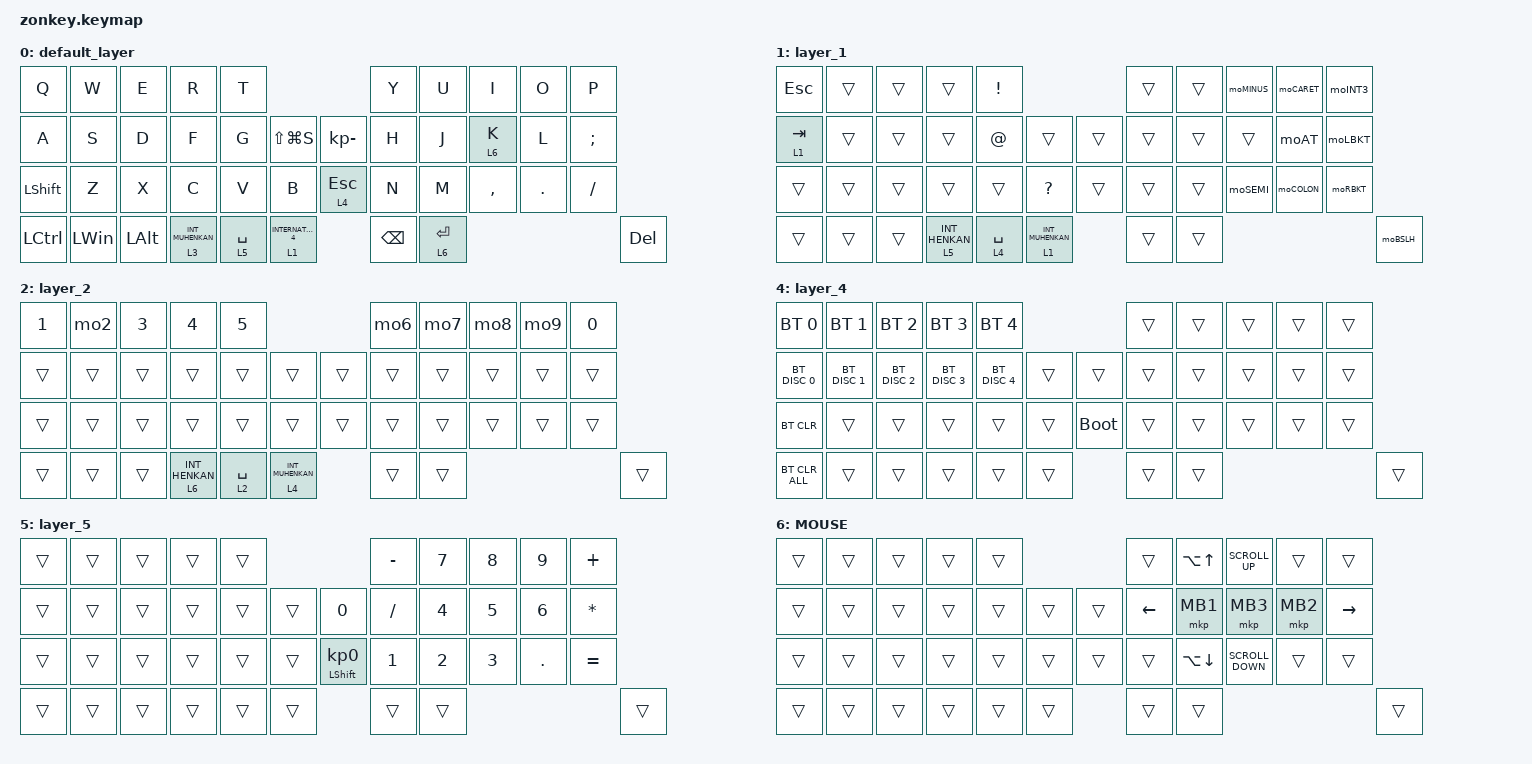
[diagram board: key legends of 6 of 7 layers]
#include <behaviors.dtsi>
#include <dt-bindings/zmk/bt.h>
#include <dt-bindings/zmk/keys.h>
#include <dt-bindings/zmk/pointing.h>

#define ZMK_POINTING_DEFAULT_SCRL_VAL 100
#define JIS 1
#define BT 4
#define MOUSE 6

&mt {
    flavor = "balanced";
    quick-tap-ms = <0>;
};

/ {
    combos { compatible = "zmk,combos"; };

    macros {
        to_layer_0: to_layer_0 {
            compatible = "zmk,behavior-macro-one-param";
            #binding-cells = <1>;
            bindings = <&to 0 &macro_param_1to1 &kp MACRO_PLACEHOLDER>;
            label = "TO_LAYER_0";
        };
    };

    behaviors {
        lt_to_layer_0: lt_to_layer_0 {
            compatible = "zmk,behavior-hold-tap";
            label = "LAYER_TAP_TO_0";
            bindings = <&mo>, <&to_layer_0>;

            #binding-cells = <2>;
            tapping-term-ms = <10>;
        };

        toJIS: toJIS {
            compatible = "zmk,behavior-hold-tap";
            label = "toJIS";
            #binding-cells = <2>;
            tapping-term-ms = <200>;
            quick-tap-ms = <0>;
            bindings = <&tog>, <&kp>;
        };

        mo2: mo2 {
            compatible = "zmk,behavior-mod-morph";
            #binding-cells = <0>;
            bindings = <&kp N2>, <&kp DQT>;

            mods = <(MOD_LSFT|MOD_RSFT)>;
        };

        mo6: mo6 {
            compatible = "zmk,behavior-mod-morph";
            #binding-cells = <0>;
            bindings = <&kp N6>, <&kp AMPS>;

            mods = <(MOD_LSFT|MOD_RSFT)>;
        };

        mo7: mo7 {
            compatible = "zmk,behavior-mod-morph";
            #binding-cells = <0>;
            bindings = <&kp N7>, <&kp APOS>;

            mods = <(MOD_LSFT|MOD_RSFT)>;
        };

        mo8: mo8 {
            compatible = "zmk,behavior-mod-morph";
            #binding-cells = <0>;
            bindings = <&kp N8>, <&kp LPAR>;

            mods = <(MOD_LSFT|MOD_RSFT)>;
        };

        mo9: mo9 {
            compatible = "zmk,behavior-mod-morph";
            #binding-cells = <0>;
            bindings = <&kp N9>, <&kp RPAR>;

            mods = <(MOD_LSFT|MOD_RSFT)>;
        };

        moMINUS: moMINUS {
            compatible = "zmk,behavior-mod-morph";
            #binding-cells = <0>;
            bindings = <&kp MINUS>, <&kp EQUAL>;

            mods = <(MOD_LSFT|MOD_RSFT)>;
        };

        moCARET: moCARET {
            compatible = "zmk,behavior-mod-morph";
            #binding-cells = <0>;
            bindings = <&kp CARET>, <&kp TILDE>;

            mods = <(MOD_LSFT|MOD_RSFT)>;
        };

        moINT3: moINT3 {
            compatible = "zmk,behavior-mod-morph";
            #binding-cells = <0>;
            bindings = <&kp INT3>, <&kp PIPE>;

            mods = <(MOD_LSFT|MOD_RSFT)>;
        };

        moAT: moAT {
            compatible = "zmk,behavior-mod-morph";
            #binding-cells = <0>;
            bindings = <&kp AT>, <&kp GRAVE>;

            mods = <(MOD_LSFT|MOD_RSFT)>;
        };

        moLBKT: moLBKT {
            compatible = "zmk,behavior-mod-morph";
            #binding-cells = <0>;
            bindings = <&kp LBKT>, <&kp LS(LBRC)>;

            mods = <(MOD_LSFT|MOD_RSFT)>;
        };

        moRBKT: moRBKT {
            compatible = "zmk,behavior-mod-morph";
            #binding-cells = <0>;
            bindings = <&kp RBKT>, <&kp LS(RBRC)>;

            mods = <(MOD_LSFT|MOD_RSFT)>;
        };

        moSEMI: moSEMI {
            compatible = "zmk,behavior-mod-morph";
            #binding-cells = <0>;
            bindings = <&kp SEMI>, <&kp PLUS>;

            mods = <(MOD_LSFT|MOD_RSFT)>;
        };

        moCOLON: moCOLON {
            compatible = "zmk,behavior-mod-morph";
            #binding-cells = <0>;
            bindings = <&kp COLON>, <&kp ASTRK>;

            mods = <(MOD_LSFT|MOD_RSFT)>;
        };

        moBSLH: moBSLH {
            compatible = "zmk,behavior-mod-morph";
            #binding-cells = <0>;
            bindings = <&kp BSLH>, <&kp UNDER>;

            mods = <(MOD_LSFT|MOD_RSFT)>;
        };

        scroll_down_up: behavior_sensor_rotate_mouse_wheel_down_up {
            compatible = "zmk,behavior-sensor-rotate";
            #sensor-binding-cells = <0>;
            bindings = <&msc SCRL_DOWN>, <&msc SCRL_UP>;

            tap-ms = <20>;
        };
    };

    keymap {
        compatible = "zmk,keymap";

        default_layer {
            bindings = <
&kp Q           &kp W         &kp E         &kp R               &kp T                                               &kp Y          &kp U        &kp I      &kp O    &kp P
&kp A           &kp S         &kp D         &kp F               &kp G        &kp LS(LG(S))            &kp KP_MINUS  &kp H          &kp J        &lt 6 K    &kp L    &kp SEMI
&kp LEFT_SHIFT  &kp Z         &kp X         &kp C               &kp V        &kp B                    &lt 4 ESCAPE  &kp N          &kp M        &kp COMMA  &kp DOT  &kp SLASH
&kp LCTRL       &kp LEFT_WIN  &kp LEFT_ALT  &lt 3 INT_MUHENKAN  &lt 5 SPACE  &lt 1 INTERNATIONAL_4                  &kp BACKSPACE  &lt 6 ENTER                                 &kp DEL
            >;

            sensor-bindings =
                <&scroll_down_up>,
                <&inc_dec_kp C_VOL_DN C_VOL_UP>;
        };

        layer_1 {
            bindings = <
&kp ESCAPE    &trans  &trans  &trans            &kp EXCLAMATION                                &trans  &trans  &moMINUS  &moCARET  &moINT3
&toJIS 1 TAB  &trans  &trans  &trans            &kp AT           &trans                &trans  &trans  &trans  &trans    &moAT     &moLBKT
&trans        &trans  &trans  &trans            &trans           &kp QUESTION          &trans  &trans  &trans  &moSEMI   &moCOLON  &moRBKT
&trans        &trans  &trans  &lt 5 INT_HENKAN  &lt 4 SPACE      &lt 1 INT_MUHENKAN            &trans  &trans                               &moBSLH
            >;

            sensor-bindings = <&inc_dec_kp RIGHT LEFT>;
        };

        layer_2 {
            bindings = <
&kp N1  &mo2    &kp N3  &kp N4            &kp N5                                     &mo6    &mo7    &mo8    &mo9    &kp N0
&trans  &trans  &trans  &trans            &trans       &trans                &trans  &trans  &trans  &trans  &trans  &trans
&trans  &trans  &trans  &trans            &trans       &trans                &trans  &trans  &trans  &trans  &trans  &trans
&trans  &trans  &trans  &lt 6 INT_HENKAN  &lt 2 SPACE  &lt 4 INT_MUHENKAN            &trans  &trans                          &trans
            >;

            sensor-bindings = <&inc_dec_kp C_VOLUME_UP C_VOLUME_DOWN>;
        };

        layer_3 {
            bindings = <
&kp F1   &kp F2   &kp F3            &kp F4       &kp F5                                &kp F6  &kp F7  &kp F8  &kp F9  &kp F10
&kp F11  &kp F12  &trans            &trans       &trans              &trans    &trans  &trans  &trans  &trans  &trans  &trans
&trans   &trans   &trans            &trans       &trans              &trans    &trans  &trans  &trans  &trans  &trans  &trans
&trans   &trans   &lt 3 INT_HENKAN  &lt 6 SPACE  &lt 5 INT_MUHENKAN  &trans            &trans  &trans
            >;

            sensor-bindings = <&scroll_down_up>;
        };

        layer_4 {
            bindings = <
&bt BT_SEL 0    &bt BT_SEL 1   &bt BT_SEL 2   &bt BT_SEL 3   &bt BT_SEL 4                          &trans  &trans  &trans  &trans  &trans
&bt BT_DISC 0   &bt BT_DISC 1  &bt BT_DISC 2  &bt BT_DISC 3  &bt BT_DISC 4  &trans    &trans       &trans  &trans  &trans  &trans  &trans
&bt BT_CLR      &trans         &trans         &trans         &trans         &trans    &bootloader  &trans  &trans  &trans  &trans  &trans
&bt BT_CLR_ALL  &trans         &trans         &trans         &trans         &trans                 &trans  &trans                          &trans
            >;

            sensor-bindings = <&scroll_down_up>;
        };

        layer_5 {
            bindings = <
&trans  &trans  &trans  &trans  &trans                                        &kp MINUS     &kp NUMBER_7  &kp NUMBER_8  &kp NUMBER_9  &kp PLUS
&trans  &trans  &trans  &trans  &trans  &trans    &kp NUMBER_0                &kp SLASH     &kp NUMBER_4  &kp NUMBER_5  &kp NUMBER_6  &kp ASTERISK
&trans  &trans  &trans  &trans  &trans  &trans    &mt LEFT_SHIFT KP_NUMBER_0  &kp NUMBER_1  &kp NUMBER_2  &kp NUMBER_3  &kp PERIOD    &kp EQUAL
&trans  &trans  &trans  &trans  &trans  &trans                                &trans        &trans                                                  &trans
            >;

            sensor-bindings = <&inc_dec_kp C_VOLUME_UP C_VOLUME_DOWN>;
        };

        MOUSE {
            bindings = <
&trans  &trans  &trans  &trans  &trans                    &trans    &kp LA(UP_ARROW)    &kp K_SCROLL_UP    &trans    &trans
&trans  &trans  &trans  &trans  &trans  &trans    &trans  &kp LEFT  &mkp MB1            &mkp MB3           &mkp MB2  &kp RIGHT
&trans  &trans  &trans  &trans  &trans  &trans    &trans  &trans    &kp LA(DOWN_ARROW)  &kp K_SCROLL_DOWN  &trans    &trans
&trans  &trans  &trans  &trans  &trans  &trans            &trans    &trans                                                      &trans
            >;

            sensor-bindings = <&scroll_down_up>;
        };
    };
};
